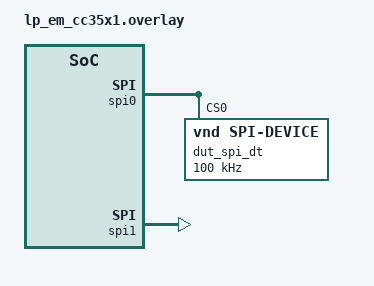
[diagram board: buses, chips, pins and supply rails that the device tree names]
/*
 * SPDX-License-Identifier: Apache-2.0
 */

&spi0 {
	status = "okay";
	dut_spi_dt: test-spi-dev@0 {
		compatible = "vnd,spi-device";
		reg = <0>;
		spi-max-frequency = <DT_FREQ_K(100)>;
	};
};

dut_spis: &spi1 {
	status = "okay";
};
